AUTOSAR XML (schema 00046)
package /DigOutParam_Inst_package
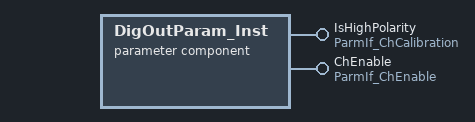
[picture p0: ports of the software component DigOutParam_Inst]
  parameter sw component type DigOutParam_Inst
    provide port IsHighPolarity: parameter-provide-com-spec{init-value=IsHighPoarity_parm:0, parameter=IsHighPoarity_parm}, provided-interface=ParmIf_ChCalibration
    provide port ChEnable: parameter-provide-com-spec{init-value=ChEnable_Parm:0, parameter=ChEnable_Parm}, provided-interface=ParmIf_ChEnable
